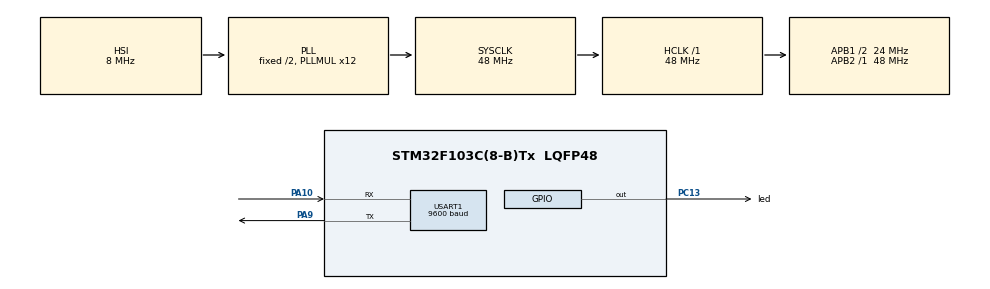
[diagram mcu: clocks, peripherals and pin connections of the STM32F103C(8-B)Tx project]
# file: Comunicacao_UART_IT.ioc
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Mcu.Family=STM32F1
Mcu.Name=STM32F103C(8-B)Tx
Mcu.Package=LQFP48
NVIC.PriorityGroup=NVIC_PRIORITYGROUP_4
NVIC.USART1_IRQn=true\:0\:0\:false\:false\:true\:true\:true\:true
PA10.Mode=Asynchronous
PA10.Signal=USART1_RX
PA9.Mode=Asynchronous
PA9.Signal=USART1_TX
PC13-TAMPER-RTC.GPIO_Label=led
PC13-TAMPER-RTC.Signal=GPIO_Output
PC14-OSC32_IN.Mode=LSE-External-Oscillator
PC14-OSC32_IN.Signal=RCC_OSC32_IN
PC15-OSC32_OUT.Mode=LSE-External-Oscillator
PC15-OSC32_OUT.Signal=RCC_OSC32_OUT
PD0-OSC_IN.Mode=HSE-External-Oscillator
PD0-OSC_IN.Signal=RCC_OSC_IN
PD1-OSC_OUT.Mode=HSE-External-Oscillator
PD1-OSC_OUT.Signal=RCC_OSC_OUT
ProjectManager.HeapSize=0x200
ProjectManager.StackSize=0x400
ProjectManager.TargetToolchain=STM32CubeIDE
RCC.AHBFreq_Value=48000000
RCC.APB1CLKDivider=RCC_HCLK_DIV2
RCC.APB1Freq_Value=24000000
RCC.APB1TimFreq_Value=48000000
RCC.APB2Freq_Value=48000000
RCC.APB2TimFreq_Value=48000000
RCC.HCLKFreq_Value=48000000
RCC.PLLMUL=RCC_PLL_MUL12
RCC.SYSCLKFreq_VALUE=48000000
RCC.SYSCLKSource=RCC_SYSCLKSOURCE_PLLCLK
RCC.USBFreq_Value=48000000
USART1.BaudRate=9600
USART1.VirtualMode=VM_ASYNC
VP_SYS_VS_ND.Mode=No_Debug
board=custom

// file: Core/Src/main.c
/* USER CODE BEGIN Header */
/**
  ******************************************************************************
  * @file           : main.c
  * @brief          : Main program body
  ******************************************************************************
  * @attention
  *
  * Copyright (c) 2024 STMicroelectronics.
  * All rights reserved.
  *
  * This software is licensed under terms that can be found in the LICENSE file
  * in the root directory of this software component.
  * If no LICENSE file comes with this software, it is provided AS-IS.
  *
  ******************************************************************************
  */

/* COMUNICAÇÃO UART COM INTERRUPÇÃO
 * monitora uart1 e transmite tudo o que for recebido em segundo plano sem
 * travar o processamento
 */

/* USER CODE END Header */
#include "main.h"

UART_HandleTypeDef huart1;

/* USER CODE BEGIN PV */

#define BUFFER_SIZE 64       // Tamanho total do buffer circular
#define MSG_MAX_SIZE 50      // Tamanho máximo esperado de uma mensagem

uint8_t rxBuffer[BUFFER_SIZE];  // Buffer circular para armazenamento de dados
volatile uint8_t rxIndex = 0;   // Índice atual no buffer circular
uint8_t rxChar = 0;

void HAL_UART_RxCpltCallback(UART_HandleTypeDef *huart) {
    if (huart->Instance == USART1) {
        if (rxIndex < BUFFER_SIZE - 1) {
            // Armazena o caractere recebido no buffer e incrementa o índice
            rxBuffer[rxIndex++] = rxChar;
        }

        // Verifica se o caractere recebido é um delimitador (neste caso, '\n') indicando o fim da mensagem
        if (rxChar == '\n' || rxIndex >= BUFFER_SIZE - 1) {
            rxBuffer[rxIndex] = '\0'; // Adiciona um caractere nulo ao final da mensagem
            processMessage(); // Chama o processamento da mensagem imediatamente
            rxIndex = 0;        // Reinicia o índice do buffer
        }

        // Reinicia a recepção de um novo caractere
        HAL_UART_Receive_IT(&huart1, &rxChar, 1);
    }
}

void processMessage(void) {
    uint8_t message[BUFFER_SIZE];  // Buffer temporário
    uint8_t messageLen = 0;

    // Copia o conteúdo do buffer para o buffer temporário
    for (int i = 0; i < BUFFER_SIZE && rxBuffer[i] != '\0'; i++) {
        message[messageLen++] = rxBuffer[i];
    }

    // Transmissão não bloqueante
    HAL_UART_Transmit_IT(&huart1, message, messageLen);
}

/* USER CODE END PV */

void SystemClock_Config(void);
static void MX_GPIO_Init(void);
static void MX_USART1_UART_Init(void);

int main(void)
{

  /* MCU Configuration--------------------------------------------------------*/

  /* Reset of all peripherals, Initializes the Flash interface and the Systick. */
  HAL_Init();

  /* Configure the system clock */
  SystemClock_Config();

  /* Initialize all configured peripherals */
  MX_GPIO_Init();
  MX_USART1_UART_Init();
  /* USER CODE BEGIN 2 */

  HAL_UART_Transmit(&huart1, (uint8_t *)"UART Interruption\r\n", sizeof("UART Interruption\r\n"), 300);

  //inicia captura do primeiro caractere
  HAL_UART_Receive_IT(&huart1, &rxChar, 1);

  /* USER CODE END 2 */

  /* Infinite loop */
  while (1)
  {

	  HAL_GPIO_TogglePin(led_GPIO_Port, led_Pin);
	  HAL_Delay(2000);

  }
}

void SystemClock_Config(void)
{
  RCC_OscInitTypeDef RCC_OscInitStruct = {0};
  RCC_ClkInitTypeDef RCC_ClkInitStruct = {0};

  /** Initializes the RCC Oscillators according to the specified parameters
  * in the RCC_OscInitTypeDef structure.
  */
  RCC_OscInitStruct.OscillatorType = RCC_OSCILLATORTYPE_HSI;
  RCC_OscInitStruct.HSIState = RCC_HSI_ON;
  RCC_OscInitStruct.HSICalibrationValue = RCC_HSICALIBRATION_DEFAULT;
  RCC_OscInitStruct.PLL.PLLState = RCC_PLL_ON;
  RCC_OscInitStruct.PLL.PLLSource = RCC_PLLSOURCE_HSI_DIV2;
  RCC_OscInitStruct.PLL.PLLMUL = RCC_PLL_MUL12;
  if (HAL_RCC_OscConfig(&RCC_OscInitStruct) != HAL_OK)
  {
    Error_Handler();
  }

  /** Initializes the CPU, AHB and APB buses clocks
  */
  RCC_ClkInitStruct.ClockType = RCC_CLOCKTYPE_HCLK|RCC_CLOCKTYPE_SYSCLK
                              |RCC_CLOCKTYPE_PCLK1|RCC_CLOCKTYPE_PCLK2;
  RCC_ClkInitStruct.SYSCLKSource = RCC_SYSCLKSOURCE_PLLCLK;
  RCC_ClkInitStruct.AHBCLKDivider = RCC_SYSCLK_DIV1;
  RCC_ClkInitStruct.APB1CLKDivider = RCC_HCLK_DIV2;
  RCC_ClkInitStruct.APB2CLKDivider = RCC_HCLK_DIV1;

  if (HAL_RCC_ClockConfig(&RCC_ClkInitStruct, FLASH_LATENCY_1) != HAL_OK)
  {
    Error_Handler();
  }
}

static void MX_USART1_UART_Init(void)
{

  huart1.Instance = USART1;
  huart1.Init.BaudRate = 9600;
  huart1.Init.WordLength = UART_WORDLENGTH_8B;
  huart1.Init.StopBits = UART_STOPBITS_1;
  huart1.Init.Parity = UART_PARITY_NONE;
  huart1.Init.Mode = UART_MODE_TX_RX;
  huart1.Init.HwFlowCtl = UART_HWCONTROL_NONE;
  huart1.Init.OverSampling = UART_OVERSAMPLING_16;
  if (HAL_UART_Init(&huart1) != HAL_OK)
  {
    Error_Handler();
  }

}

static void MX_GPIO_Init(void)
{
  GPIO_InitTypeDef GPIO_InitStruct = {0};

  /* GPIO Ports Clock Enable */
  __HAL_RCC_GPIOC_CLK_ENABLE();
  __HAL_RCC_GPIOD_CLK_ENABLE();
  __HAL_RCC_GPIOA_CLK_ENABLE();

  /*Configure GPIO pin Output Level */
  HAL_GPIO_WritePin(led_GPIO_Port, led_Pin, GPIO_PIN_RESET);

  /*Configure GPIO pin : led_Pin */
  GPIO_InitStruct.Pin = led_Pin;
  GPIO_InitStruct.Mode = GPIO_MODE_OUTPUT_PP;
  GPIO_InitStruct.Pull = GPIO_NOPULL;
  GPIO_InitStruct.Speed = GPIO_SPEED_FREQ_LOW;
  HAL_GPIO_Init(led_GPIO_Port, &GPIO_InitStruct);

}

void Error_Handler(void)
{
  __disable_irq();
  while (1)
  {
  }
}
